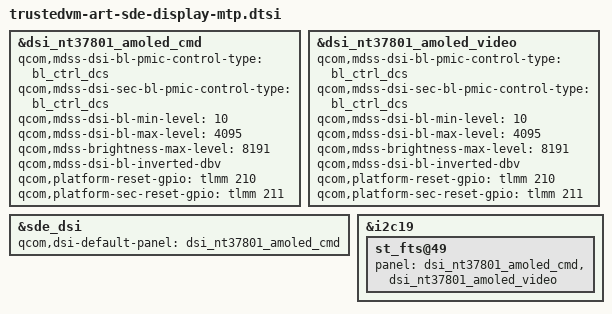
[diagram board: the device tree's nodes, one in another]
// SPDX-License-Identifier: BSD-3-Clause
/*
 * Copyright (c) Qualcomm Technologies, Inc. and/or its subsidiaries.
 */

#include "trustedvm-art-sde-display.dtsi"

&dsi_nt37801_amoled_cmd {
	qcom,mdss-dsi-bl-pmic-control-type = "bl_ctrl_dcs";
	qcom,mdss-dsi-sec-bl-pmic-control-type = "bl_ctrl_dcs";
	qcom,mdss-dsi-bl-min-level = <10>;
	qcom,mdss-dsi-bl-max-level = <4095>;
	qcom,mdss-brightness-max-level = <8191>;
	qcom,mdss-dsi-bl-inverted-dbv;
	qcom,platform-reset-gpio = <&tlmm 210 0>;
	qcom,platform-sec-reset-gpio = <&tlmm 211 0>;
};

&dsi_nt37801_amoled_video {
	qcom,mdss-dsi-bl-pmic-control-type = "bl_ctrl_dcs";
	qcom,mdss-dsi-sec-bl-pmic-control-type = "bl_ctrl_dcs";
	qcom,mdss-dsi-bl-min-level = <10>;
	qcom,mdss-dsi-bl-max-level = <4095>;
	qcom,mdss-brightness-max-level = <8191>;
	qcom,mdss-dsi-bl-inverted-dbv;
	qcom,platform-reset-gpio = <&tlmm 210 0>;
	qcom,platform-sec-reset-gpio = <&tlmm 211 0>;
};

&sde_dsi {
	qcom,dsi-default-panel = <&dsi_nt37801_amoled_cmd>;
};

&i2c19 {
	st_fts@49 {
		panel = <&dsi_nt37801_amoled_cmd
			&dsi_nt37801_amoled_video>;
	};
};

